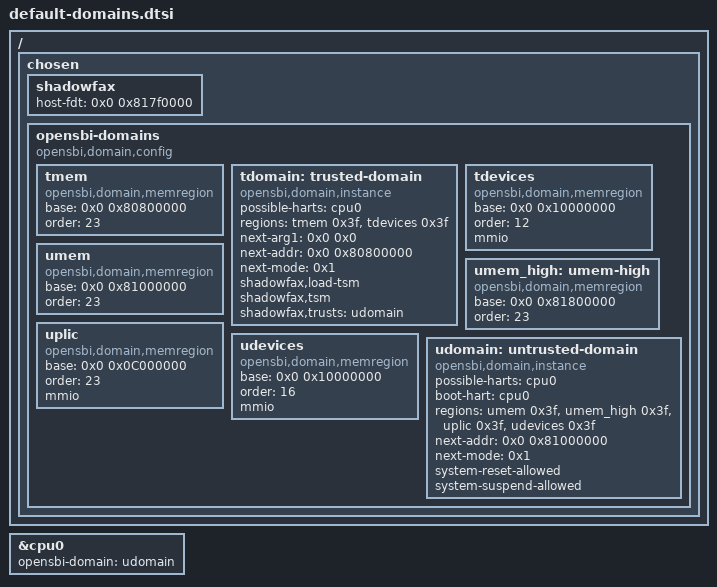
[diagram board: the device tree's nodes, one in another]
/ {
	chosen {
		shadowfax {
			host-fdt = <0x0 0x817f0000>;
		};

		opensbi-domains {
			compatible = "opensbi,domain,config";

			tmem: tmem {
				compatible = "opensbi,domain,memregion";
				base = <0x0 0x80800000>;
				order = <23>;
			};

			tdomain: trusted-domain {
				compatible = "opensbi,domain,instance";
				possible-harts = <&cpu0>;
				regions = <&tmem 0x3f>, <&tdevices 0x3f>;
				next-arg1 = <0x0 0x0>;
				next-addr = <0x0 0x80800000>;
				next-mode = <0x1>;
				shadowfax,load-tsm;
				shadowfax,tsm;
				shadowfax,trusts = <&udomain>;
			};

			tdevices: tdevices {
				compatible = "opensbi,domain,memregion";
				base = <0x0 0x10000000>;
				order = <12>;
				mmio;
			};

			umem: umem {
				compatible = "opensbi,domain,memregion";
				base = <0x0 0x81000000>;
				order = <23>;
			};

			umem_high: umem-high {
				compatible = "opensbi,domain,memregion";
				base = <0x0 0x81800000>;
				order = <23>;
			};

			uplic: uplic {
				compatible = "opensbi,domain,memregion";
				base = <0x0 0x0C000000>;
				order = <23>;
				mmio;
			};

			udevices: udevices {
				compatible = "opensbi,domain,memregion";
				base = <0x0 0x10000000>;
				order = <16>;
				mmio;
			};

			udomain: untrusted-domain {
				compatible = "opensbi,domain,instance";
				possible-harts = <&cpu0>;
				boot-hart = <&cpu0>;
				regions = <&umem 0x3f>, <&umem_high 0x3f>, <&uplic 0x3f>, <&udevices 0x3f>;
				next-addr = <0x0 0x81000000>;
				next-mode = <0x1>;
				system-reset-allowed;
				system-suspend-allowed;
			};

		};
	};
};

/* OpenSBI assigns a hart to a domain from the CPU node's opensbi-domain
   phandle (fdt_domain.c, __fdt_parse_domain); possible-harts and boot-hart
   only declare eligibility. Without this the hart stays in the root domain,
   so a launcher calls the TSM as domain 0 and every trust-map check fails.
   base.dtsi cannot carry it: the owning domain differs per tree. */
&cpu0 {
	opensbi-domain = <&udomain>;
};
